# UPD70F3508 register map
Vendor: Renesas; Series: V850E2/Px4; File version: 1.0
CPU: other r0p0, little endian, no MPU, FPU, 4 interrupt priority bits
Registers are 8-bit, read-write, reset 0x0 unless marked. A register's access mark holds for its fields unless they carry their own. Offsets are from the block's base; [hi:lo] are bit positions; {n}, {i} and the like mark numbered series.

## WDTA0 — Window Watchdog Timer A, instance 0
Base 0xFF806000
0x00 WDTA0WDTE reset 0x2C — WDTA0 Enable Register — start control and trigger register; write 0xAC to trigger
  [7] WDTA0RUN — WDTA0 enable: 0=disabled, 1=enabled; cleared only by reset once set
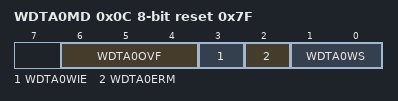
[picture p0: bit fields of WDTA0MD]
0x0C WDTA0MD reset 0x7F — WDTA0 Mode Register — overflow time, 75% interrupt, error mode, window-open period
  [6:4] WDTA0OVF — Overflow time select [OVF2:OVF1:OVF0]: 000=2^9, 001=2^10, 010=2^11, 011=2^12, 100=2^13, 101=2^14, 110=2^15, 111=2^16 (all /WDTATCKI)
  [3] WDTA0WIE — 75% interrupt enable: 0=WDTAnTIT disabled, 1=WDTAnTIT enabled
  [2] WDTA0ERM — Error mode select: 0=NMI request mode (WDTAnTNMI), 1=Reset mode (WDTAnTRES)
  [1:0] WDTA0WS — Window-open period [WS1:WS0]: 00=25%, 01=50%, 10=75%, 11=100%

## TAUJ0_CFG — Timer Array Unit J 0 - Configuration Registers (base0)
Base 0xFF811080
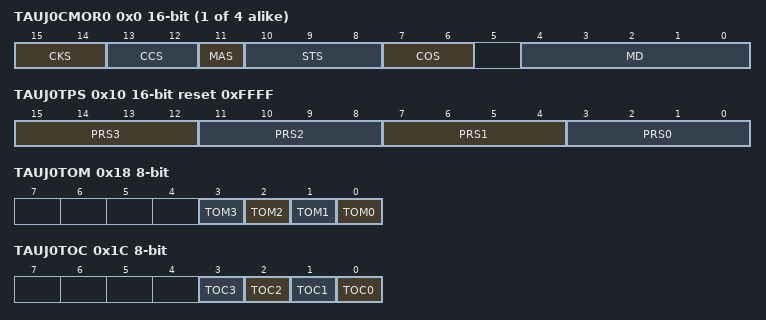
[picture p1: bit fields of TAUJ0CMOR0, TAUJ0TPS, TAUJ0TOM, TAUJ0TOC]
{0x0+4i} TAUJ0CMOR{i} 16-bit (i=0..3) — TAUJn Channel Mode OS Register {i}
  [15:14] CKS — Sampling clock select [1:0]
  [13:12] CCS — Count clock select [1:0]
  [11] MAS — Master/slave select (even channels only)
  [10:8] STS — External start trigger select [2:0]
  [7:6] COS — Capture register update timing [1:0]
  [4:0] MD — Operating mode [4:0]
0x10 TAUJ0TPS 16-bit reset 0xFFFF — TAUJn Prescaler Clock Select Register
  [15:12] PRS3 — CK3_PRE clock prescaler select [3:0]
  [11:8] PRS2 — CK2 clock prescaler select [3:0]
  [7:4] PRS1 — CK1 clock prescaler select [3:0]
  [3:0] PRS0 — CK0 clock prescaler select [3:0]
0x14 TAUJ0BRS — TAUJn Prescaler Baud Rate Setting Register
  [7:0] BRS — CK3_PRE division factor for CK3 [7:0]
0x18 TAUJ0TOM — TAUJn Channel Output Mode Register
  [n] TOM{n} (n=0..3) — Channel {n} output mode (0=independent, 1=synchronous)
0x1C TAUJ0TOC — TAUJn Channel Output Configuration Register
  [n] TOC{n} (n=0..3) — Channel {n} output configuration (0=toggle mode)
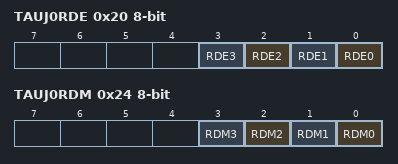
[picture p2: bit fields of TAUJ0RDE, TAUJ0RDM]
0x20 TAUJ0RDE — TAUJn Channel Reload Data Enable Register
  [n] RDE{n} (n=0..3) — Channel {n} simultaneous rewrite enable
0x24 TAUJ0RDM — TAUJn Channel Reload Data Mode Register
  [n] RDM{n} (n=0..3) — Channel {n} simultaneous rewrite trigger timing select

## TAUJ1_CFG — Timer Array Unit J 1 - Configuration Registers (base0)
Base 0xFF812080
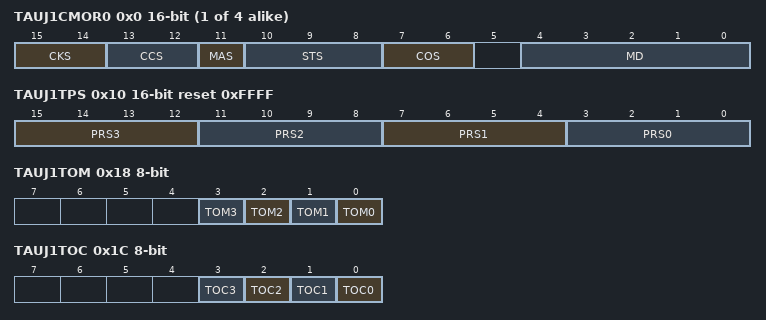
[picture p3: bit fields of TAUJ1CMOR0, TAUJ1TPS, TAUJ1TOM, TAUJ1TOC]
{0x0+4i} TAUJ1CMOR{i} 16-bit (i=0..3) — TAUJn Channel Mode OS Register {i}
  [15:14] CKS — Sampling clock select [1:0]
  [13:12] CCS — Count clock select [1:0]
  [11] MAS — Master/slave select (even channels only)
  [10:8] STS — External start trigger select [2:0]
  [7:6] COS — Capture register update timing [1:0]
  [4:0] MD — Operating mode [4:0]
0x10 TAUJ1TPS 16-bit reset 0xFFFF — TAUJn Prescaler Clock Select Register
  [15:12] PRS3 — CK3_PRE clock prescaler select [3:0]
  [11:8] PRS2 — CK2 clock prescaler select [3:0]
  [7:4] PRS1 — CK1 clock prescaler select [3:0]
  [3:0] PRS0 — CK0 clock prescaler select [3:0]
0x14 TAUJ1BRS — TAUJn Prescaler Baud Rate Setting Register
  [7:0] BRS — CK3_PRE division factor for CK3 [7:0]
0x18 TAUJ1TOM — TAUJn Channel Output Mode Register
  [n] TOM{n} (n=0..3) — Channel {n} output mode (0=independent, 1=synchronous)
0x1C TAUJ1TOC — TAUJn Channel Output Configuration Register
  [n] TOC{n} (n=0..3) — Channel {n} output configuration (0=toggle mode)
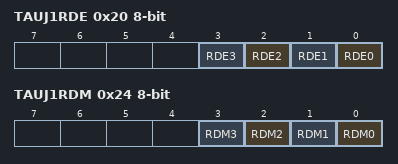
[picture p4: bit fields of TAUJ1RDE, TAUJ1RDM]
0x20 TAUJ1RDE — TAUJn Channel Reload Data Enable Register
  [n] RDE{n} (n=0..3) — Channel {n} simultaneous rewrite enable
0x24 TAUJ1RDM — TAUJn Channel Reload Data Mode Register
  [n] RDM{n} (n=0..3) — Channel {n} simultaneous rewrite trigger timing select

## TAPA0_CTL — Timer Option Module 0 Control Registers (base0 region)
Base 0xFF815020
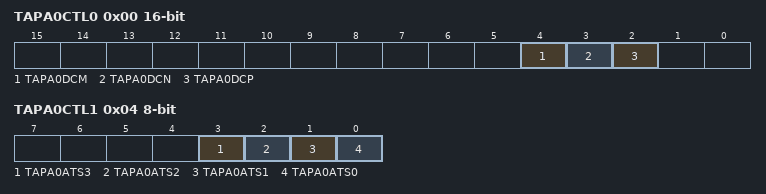
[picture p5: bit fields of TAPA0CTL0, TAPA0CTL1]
0x00 TAPA0CTL0 16-bit — TAPA0 Control Register 0 - Hi-Z edge/mode control
  [4] TAPA0DCM — Clearing condition specification bit
  [3] TAPA0DCN — Hi-Z input edge selection bit N (falling)
  [2] TAPA0DCP — Hi-Z input edge selection bit P (rising)
0x04 TAPA0CTL1 — TAPA0 Control Register 1 - A/D converter trigger select (n=0,1 only)
  [3] TAPA0ATS3 — A/D converter trigger 1 select bit 1
  [2] TAPA0ATS2 — A/D converter trigger 1 select bit 0
  [1] TAPA0ATS1 — A/D converter trigger 0 select bit 1
  [0] TAPA0ATS0 — A/D converter trigger 0 select bit 0
